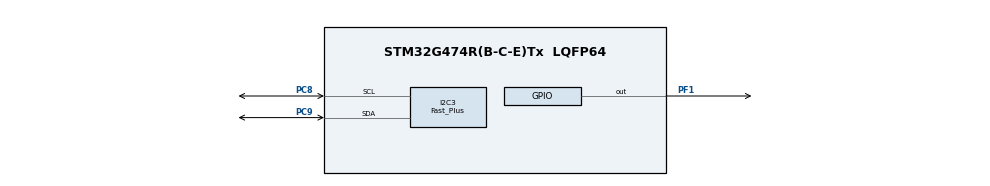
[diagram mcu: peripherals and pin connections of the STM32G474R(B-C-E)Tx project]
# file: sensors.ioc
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CRC.DefaultPolynomialUse=DEFAULT_POLYNOMIAL_ENABLE
I2C3.I2C_Speed_Mode=I2C_Fast_Plus
I2C3.Timing=0x10B30F25
Mcu.Family=STM32G4
Mcu.Name=STM32G474R(B-C-E)Tx
Mcu.Package=LQFP64
NVIC.PriorityGroup=NVIC_PRIORITYGROUP_4
NVIC.TIM1_UP_TIM16_IRQn=true\:15\:0\:false\:false\:true\:false\:true\:true
NVIC.TimeBase=TIM1_UP_TIM16_IRQn
NVIC.TimeBaseIP=TIM1
PA13.Mode=Trace_Asynchronous_SW
PA13.Signal=SYS_JTMS-SWDIO
PA14.Mode=Trace_Asynchronous_SW
PA14.Signal=SYS_JTCK-SWCLK
PB3.Mode=Trace_Asynchronous_SW
PB3.Signal=SYS_JTDO-SWO
PC8.Mode=I2C
PC8.Signal=I2C3_SCL
PC9.Mode=I2C
PC9.Signal=I2C3_SDA
PF0-OSC_IN.Mode=HSE-External-Clock-Source
PF0-OSC_IN.Signal=RCC_OSC_IN
PF1-OSC_OUT.Signal=GPIO_Output
ProjectManager.HeapSize=0x200
ProjectManager.StackSize=0x400
ProjectManager.TargetToolchain=CMake
RCC.ADC12Freq_Value=160000000
RCC.ADC345Freq_Value=160000000
RCC.AHBFreq_Value=160000000
RCC.APB1Freq_Value=160000000
RCC.APB1TimFreq_Value=160000000
RCC.APB2Freq_Value=160000000
RCC.APB2TimFreq_Value=160000000
RCC.CortexFreq_Value=160000000
RCC.EXTERNAL_CLOCK_VALUE=12288000
RCC.HCLKFreq_Value=160000000
RCC.HSE_VALUE=8000000
RCC.HSI48_VALUE=48000000
RCC.HSI_VALUE=16000000
RCC.I2C2CLockSelection=RCC_I2C2CLKSOURCE_SYSCLK
RCC.I2C3CLockSelection=RCC_I2C3CLKSOURCE_SYSCLK
RCC.I2C4CLockSelection=RCC_I2C4CLKSOURCE_SYSCLK
RCC.LSE_VALUE=32768
RCC.PLLN=40
RCC.PLLSourceVirtual=RCC_PLLSOURCE_HSE
RCC.SYSCLKFreq_VALUE=160000000
RCC.SYSCLKSource=RCC_SYSCLKSOURCE_PLLCLK
RCC.USBFreq_Value=160000000
RCC.VCOOutputFreq_Value=320000000
VP_CRC_VS_CRC.Mode=CRC_Activate
VP_SYS_VS_DBSignals.Mode=DisableDeadBatterySignals
VP_SYS_VS_tim1.Mode=TIM1
board=custom

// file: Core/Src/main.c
/* USER CODE BEGIN Header */
/**
  ******************************************************************************
  * @file           : main.c
  * @brief          : Main program body
  ******************************************************************************
  * @attention
  *
  * Copyright (c) 2024 STMicroelectronics.
  * All rights reserved.
  *
  * This software is licensed under terms that can be found in the LICENSE file
  * in the root directory of this software component.
  * If no LICENSE file comes with this software, it is provided AS-IS.
  *
  ******************************************************************************
  */
/* USER CODE END Header */
#include "main.h"
#include "crc.h"
#include "i2c.h"
#include "gpio.h"

/* USER CODE BEGIN Includes */
#include <stdio.h>
#include "vl53l0x_api.h"
//#include "circularBuffer.h"
/* USER CODE END Includes */

/* USER CODE BEGIN PD */
#ifdef __GNUC__
#define PUTCHAR_PROTOTYPE int __io_putchar(int ch)
#else
#define PUTCHAR_PROTOTYPE int fputc(int ch, FILE *f)
#endif
/* USER CODE END PD */

/* USER CODE BEGIN PM */
PUTCHAR_PROTOTYPE
{
  ITM_SendChar(ch);
  return ch;
}
//CircularBuffer *cb;
/* USER CODE END PM */

/* USER CODE BEGIN PV */
// FDCAN_RxHeaderTypeDef RxHeader_FDCAN2;
VL53L0X_Dev_t dev = {.I2cHandle = &hi2c3, .I2cDevAddr = 0x52};
/* USER CODE END PV */

void SystemClock_Config(void);

/* USER CODE BEGIN 0 */
/*
I2C2 - is meant for thermal sensor MLX90640 and is ran using DMA to offload CPU for calculations
     - still need to fully test but ideally implmentation is done

 */
/* USER CODE END 0 */

int main(void)
{

  /* USER CODE BEGIN 1 */
  //cb = circular_buffer_init(64, 68 * sizeof(uint8_t));
  /* USER CODE END 1 */

  /* MCU Configuration--------------------------------------------------------*/

  /* Reset of all peripherals, Initializes the Flash interface and the Systick. */
  HAL_Init();

  /* Configure the system clock */
  SystemClock_Config();

  /* Initialize all configured peripherals */
  MX_GPIO_Init();
  MX_I2C3_Init();
  MX_CRC_Init();
  /* USER CODE BEGIN 2 */

  // HAL_FDCAN_Start(&hfdcan1);
  // HAL_FDCAN_Start(&hfdcan2);
  // HAL_FDCAN_ActivateNotification(&hfdcan1, FDCAN_IT_RX_FIFO0_NEW_MESSAGE, 0);
  // HAL_FDCAN_ActivateNotification(&hfdcan2, FDCAN_IT_RX_FIFO0_NEW_MESSAGE, 0);

  // static uint16_t eeMLX90640[832];
  // static paramsMLX90640 mlx90640;
  // #define MLX90640_ADDRESS 0x33<<1
  // MLX90640_DumpEE(MLX90640_ADDRESS, eeMLX90640);

  // MLX90640_ExtractParameters(eeMLX90640, &mlx90640);

  // MLX90640_SetRefreshRate(MLX90640_ADDRESS, 0x05);

  // MLX90640_SynchFrame(MLX90640_ADDRESS);
  //  MLX90640_SetRefreshRate(0x33, 0x05);
  /* USER CODE END 2 */

  /* Infinite loop */
  /* USER CODE BEGIN WHILE */

  // unsigned char slaveAddress;
  // slaveAddress = 0x33<<1;
  // static uint16_t eeMLX90640[832];
  // static uint16_t mlx90640Frame[834];
  // paramsMLX90640 mlx90640;
  // static float mlx90640Image[768];
  // int status;
  // status = MLX90640_DumpEE (slaveAddress, eeMLX90640);
  // status = MLX90640_ExtractParameters(eeMLX90640, &mlx90640);
  // status = MLX90640_SetRefreshRate (slaveAddress, 0x05);
  // // status = MLX90640_TriggerMeasurement (slaveAddress);
  // status = MLX90640_GetFrameData (0x33, mlx90640Frame);
  // // status = MLX90640_GetFrameData (0x33, mlx90640Frame);
  // MLX90640_GetImage(mlx90640Frame, &mlx90640, mlx90640Image);
  //uint16_t pressure = 0;
  VL53L0X_WaitDeviceBooted(&dev);
  VL53L0X_DataInit(&dev);
  VL53L0X_DeviceParameters_t  params = {0};
  VL53L0X_GetDeviceParameters(&dev, &params);
  params.DeviceMode = VL53L0X_DEVICEMODE_CONTINUOUS_RANGING;
  VL53L0X_SetDeviceParameters(&dev, &params);
  VL53L0X_GetDeviceParameters(&dev, &params);
  VL53L0X_GetMeasurementTimingBudgetMicroSeconds(&dev, &params.MeasurementTimingBudgetMicroSeconds);
  int status = VL53L0X_SetMeasurementTimingBudgetMicroSeconds(&dev, 25000);
  // VL53L0X_PerformSingleMeasurement(&dev);
  VL53L0X_StartMeasurement(&dev);
  VL53L0X_ClearInterruptMask(&dev, 0);
  VL53L0X_RangingMeasurementData_t measure = {0};

  uint8_t TxData[8] = {0x10, 0x32, 0x54, 0x76, 0x98, 0x00, 0x11, 0x22};
  // FDCAN_TxHeaderTypeDef TxHeader;
  // TxHeader.Identifier = 0x3FF;
  // TxHeader.IdType = FDCAN_STANDARD_ID;
  // TxHeader.TxFrameType = FDCAN_DATA_FRAME;
  // TxHeader.DataLength = FDCAN_DLC_BYTES_8;
  // TxHeader.ErrorStateIndicator = FDCAN_ESI_ACTIVE;
  // TxHeader.BitRateSwitch = FDCAN_BRS_OFF;
  // TxHeader.FDFormat = FDCAN_CLASSIC_CAN;
  // TxHeader.TxEventFifoControl = FDCAN_NO_TX_EVENTS;
  // TxHeader.MessageMarker = 0;

  while (1)
  {
    int status;
    VL53L0X_GetMeasurementDataReady(&dev, &status);
    VL53L0X_GetRangingMeasurementData(&dev, &measure);
    printf("Distance: %d\n", measure.RangeMilliMeter);
    VL53L0X_ClearInterruptMask(&dev, 0);
    HAL_GPIO_TogglePin(GPIOF, GPIO_PIN_1);
    // HAL_FDCAN_AddMessageToTxFifoQ(&hfdcan1, &TxHeader, TxData);
    // HAL_FDCAN_AddMessageToTxFifoQ(&hfdcan2, &TxHeader, TxData);
    /* USER CODE END WHILE */

  }
}

void SystemClock_Config(void)
{
  LL_FLASH_SetLatency(LL_FLASH_LATENCY_4);
  while(LL_FLASH_GetLatency() != LL_FLASH_LATENCY_4)
  {
  }
  LL_PWR_EnableRange1BoostMode();
  LL_RCC_HSE_EnableBypass();
  LL_RCC_HSE_Enable();
   /* Wait till HSE is ready */
  while(LL_RCC_HSE_IsReady() != 1)
  {
  }

  LL_RCC_PLL_ConfigDomain_SYS(LL_RCC_PLLSOURCE_HSE, LL_RCC_PLLM_DIV_1, 40, LL_RCC_PLLR_DIV_2);
  LL_RCC_PLL_EnableDomain_SYS();
  LL_RCC_PLL_Enable();
   /* Wait till PLL is ready */
  while(LL_RCC_PLL_IsReady() != 1)
  {
  }

  LL_RCC_SetSysClkSource(LL_RCC_SYS_CLKSOURCE_PLL);
  LL_RCC_SetAHBPrescaler(LL_RCC_SYSCLK_DIV_2);
   /* Wait till System clock is ready */
  while(LL_RCC_GetSysClkSource() != LL_RCC_SYS_CLKSOURCE_STATUS_PLL)
  {
  }

  /* Insure 1us transition state at intermediate medium speed clock*/
  for (__IO uint32_t i = (170 >> 1); i !=0; i--);

  /* Set AHB prescaler*/
  LL_RCC_SetAHBPrescaler(LL_RCC_SYSCLK_DIV_1);
  LL_RCC_SetAPB1Prescaler(LL_RCC_APB1_DIV_1);
  LL_RCC_SetAPB2Prescaler(LL_RCC_APB2_DIV_1);
  LL_SetSystemCoreClock(160000000);

   /* Update the time base */
  if (HAL_InitTick (TICK_INT_PRIORITY) != HAL_OK)
  {
    Error_Handler();
  }
}

/* USER CODE BEGIN 4 */
// void HAL_FDCAN_RxFifo0Callback(FDCAN_HandleTypeDef *hfdcan, uint32_t RxFifo0ITs)
// {
//   uint8_t RxData[64];
//   HAL_FDCAN_GetRxMessage(hfdcan, FDCAN_RX_FIFO0, &RxHeader_FDCAN2, RxData);
//   printf("got messgae\n");
//   //circularBufferPush(cb, RxData, sizeof(RxData));

// }
/* USER CODE END 4 */

void HAL_TIM_PeriodElapsedCallback(TIM_HandleTypeDef *htim)
{
  if (htim->Instance == TIM1) {
    HAL_IncTick();
  }
}

void Error_Handler(void)
{
  __disable_irq();
  while (1)
  {
  }
}
